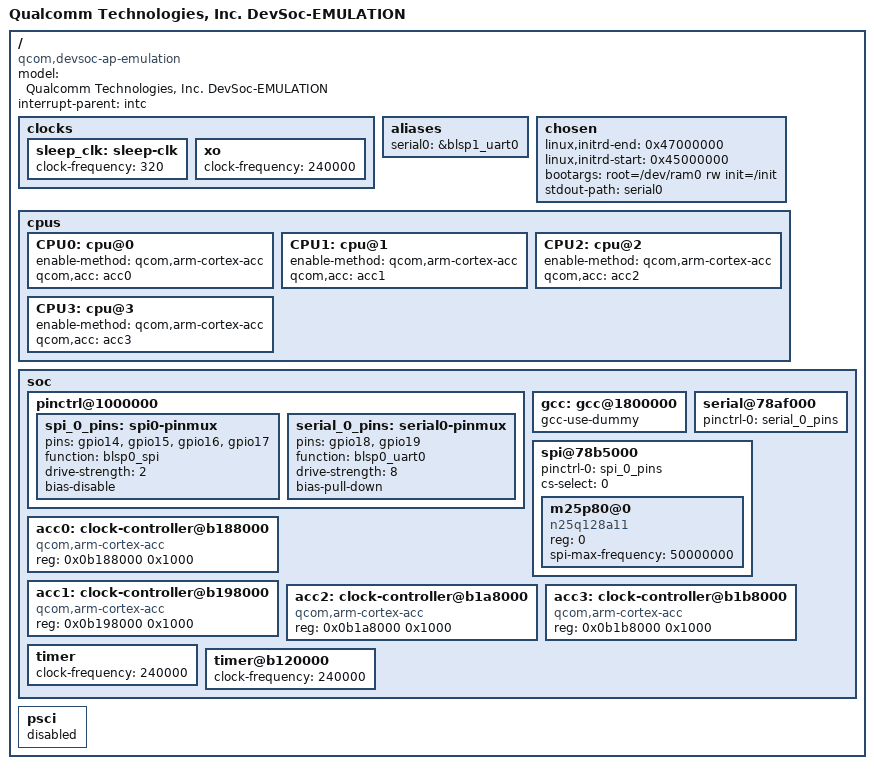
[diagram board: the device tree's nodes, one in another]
// SPDX-License-Identifier: (GPL-2.0+ OR BSD-3-Clause)
/*
 * Dev SoC Emulation board device tree source
 *
 * Copyright (c) 2020-2021 The Linux Foundation. All rights reserved.
 * Copyright (c) 2022 Qualcomm Innovation Center, Inc. All rights reserved.
 */

/dts-v1/;

#include "devsoc.dtsi"
#include "devsoc-default-memory.dtsi"

/ {
	#address-cells = <0x2>;
	#size-cells = <0x2>;
	model = "Qualcomm Technologies, Inc. DevSoc-EMULATION";
	compatible = "qcom,devsoc-ap-emulation", "qcom,devsoc";
	interrupt-parent = <&intc>;

	clocks {
		sleep_clk: sleep-clk {
			clock-frequency = <320>;
		};

		xo: xo {
			clock-frequency = <240000>;
		};
	};

	aliases {
		serial0 = &blsp1_uart0;
	};

	chosen {
		linux,initrd-end = <0x47000000>;
		linux,initrd-start = <0x45000000>;
		bootargs = "root=/dev/ram0 rw init=/init";
		stdout-path = "serial0";
	};

	cpus: cpus {
		CPU0: cpu@0 {
			enable-method = "qcom,arm-cortex-acc";
			qcom,acc = <&acc0>;
		};

		CPU1: cpu@1 {
			enable-method = "qcom,arm-cortex-acc";
			qcom,acc = <&acc1>;
		};

		CPU2: cpu@2 {
			enable-method = "qcom,arm-cortex-acc";
			qcom,acc = <&acc2>;
		};

		CPU3: cpu@3 {
			enable-method = "qcom,arm-cortex-acc";
			qcom,acc = <&acc3>;
		};
	};

	soc {
		pinctrl@1000000 {
			spi_0_pins: spi0-pinmux {
				pins = "gpio14", "gpio15", "gpio16", "gpio17";
				function = "blsp0_spi";
				drive-strength = <2>;
				bias-disable;
			};

			serial_0_pins: serial0-pinmux {
				pins = "gpio18", "gpio19";
				function = "blsp0_uart0";
				drive-strength = <8>;
				bias-pull-down;
			};
		};

		gcc: gcc@1800000 {
			gcc-use-dummy;
		};

		serial@78af000 {
			pinctrl-0 = <&serial_0_pins>;
			pinctrl-names = "default";
			status = "ok";
		};

		spi@78b5000 {
			pinctrl-0 = <&spi_0_pins>;
			pinctrl-names = "default";
			cs-select = <0>;
			status = "ok";

			m25p80@0 {
				compatible = "n25q128a11";
				#address-cells = <1>;
				#size-cells = <1>;
				reg = <0>;
				spi-max-frequency = <50000000>;
			};
		};

		acc0: clock-controller@b188000 {
			compatible = "qcom,arm-cortex-acc";
			reg = <0x0b188000 0x1000>;
		};

		acc1: clock-controller@b198000 {
			compatible = "qcom,arm-cortex-acc";
			reg = <0x0b198000 0x1000>;
		};

		acc2:clock-controller@b1a8000 {
			compatible = "qcom,arm-cortex-acc";
			reg = <0x0b1a8000 0x1000>;
		};

		acc3:clock-controller@b1b8000 {
			compatible = "qcom,arm-cortex-acc";
			reg = <0x0b1b8000 0x1000>;
		};

		/*Timer freq for rumi = timer freq / 100*/
		timer {
			clock-frequency = <240000>;
		};

		timer@b120000 {
			clock-frequency = <240000>;
		};
	};

	psci {
		status = "disabled";
	};

};
